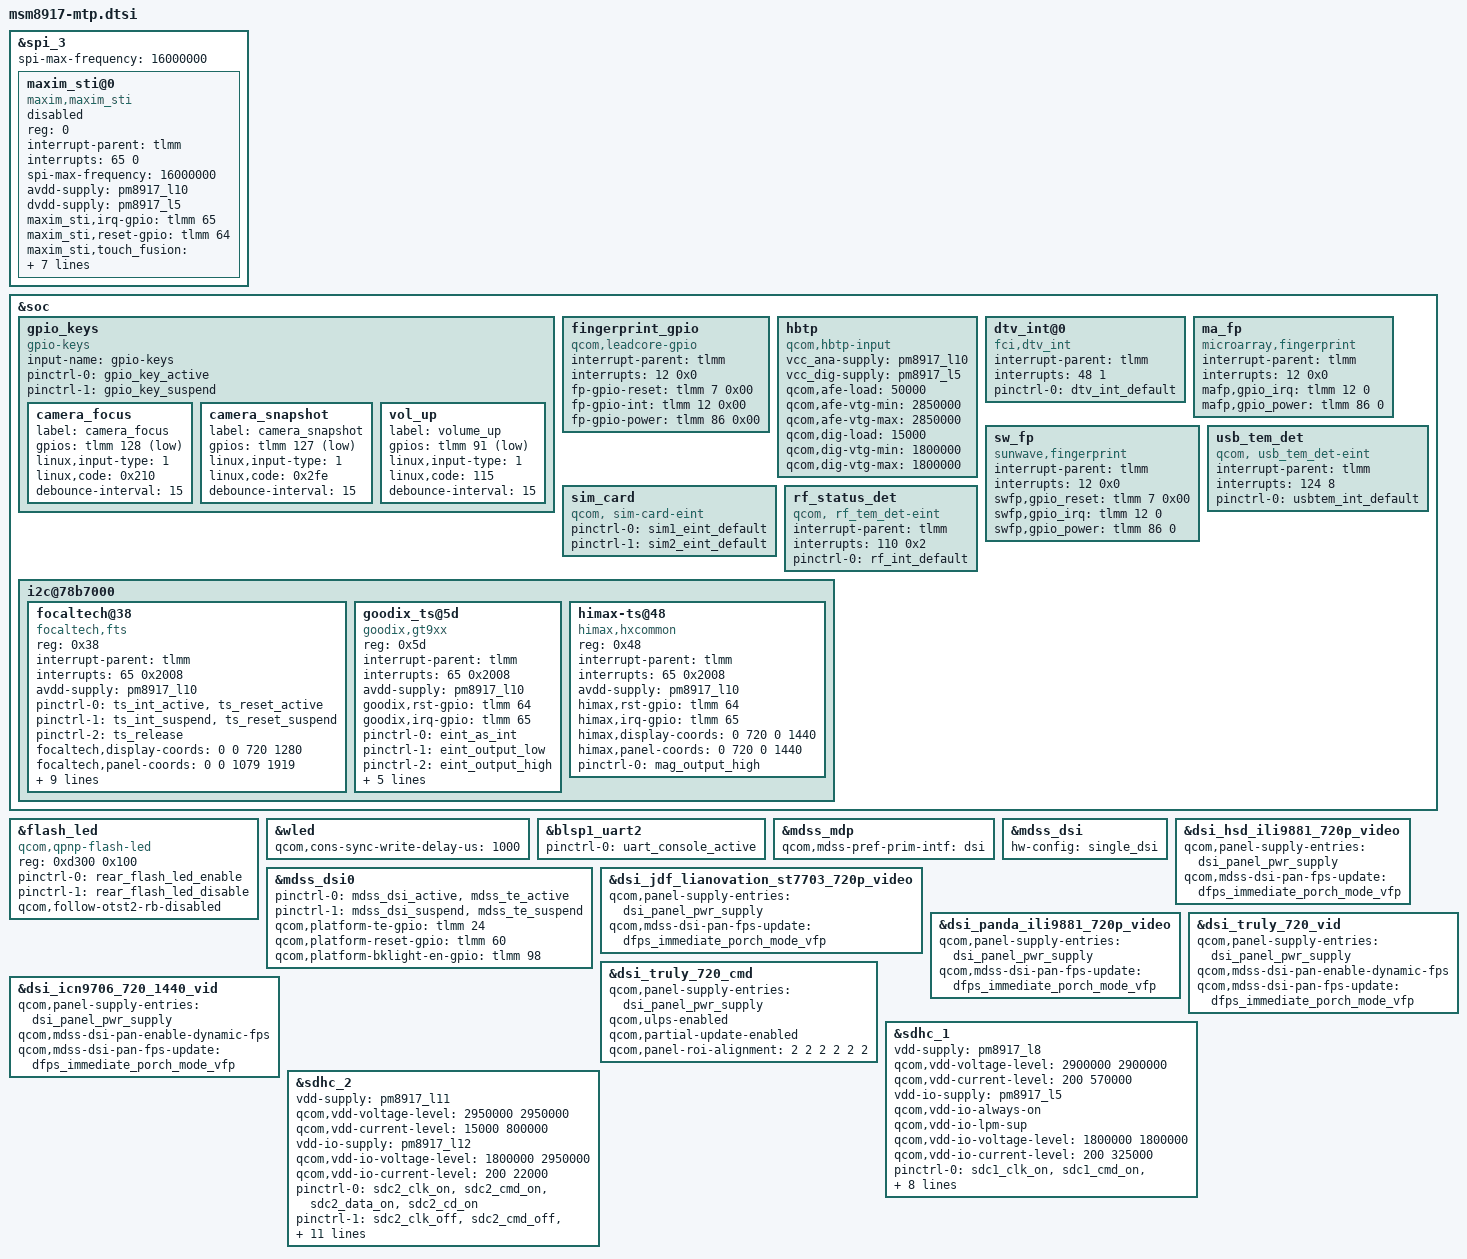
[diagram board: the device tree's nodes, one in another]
/*
 * Copyright (c) 2015-2017, The Linux Foundation. All rights reserved.
 *
 * This program is free software; you can redistribute it and/or modify
 * it under the terms of the GNU General Public License version 2 and
 * only version 2 as published by the Free Software Foundation.
 *
 * This program is distributed in the hope that it will be useful,
 * but WITHOUT ANY WARRANTY; without even the implied warranty of
 * MERCHANTABILITY or FITNESS FOR A PARTICULAR PURPOSE.  See the
 * GNU General Public License for more details.
 */

#include "msm8917-pinctrl.dtsi"
#include "msm8917-camera-sensor-mtp.dtsi"

&spi_3 { /* BLSP1 QUP3 */
	spi-max-frequency = <16000000>;
	maxim_sti@0 {
		status = "disabled";
		compatible = "maxim,maxim_sti";
		reg = <0>;
		interrupt-parent = <&tlmm>;
		interrupts = <65 0>;
		spi-max-frequency = <16000000>;
		avdd-supply = <&pm8917_l10>;
		dvdd-supply = <&pm8917_l5>;
		maxim_sti,irq-gpio = <&tlmm 65 0x00>;
		maxim_sti,reset-gpio = <&tlmm 64 0x00>;
		maxim_sti,touch_fusion = "/vendor/bin/touch_fusion";
		maxim_sti,config_file = "/etc/firmware/qtc800s.cfg";
		maxim_sti,fw_name = "qtc800s.bin";
		pinctrl-names = "pmx_ts_active","pmx_ts_suspend",
			"pmx_ts_release";
		pinctrl-0 = <&ts_int_active &ts_reset_active>;
		pinctrl-1 = <&ts_int_suspend &ts_reset_suspend>;
		pinctrl-2 = <&ts_release>;
	};
};

&soc {
	gpio_keys {
		compatible = "gpio-keys";
		input-name = "gpio-keys";
		pinctrl-names = "tlmm_gpio_key_active","tlmm_gpio_key_suspend";
		pinctrl-0 = <&gpio_key_active>;
		pinctrl-1 = <&gpio_key_suspend>;

		camera_focus {
			label = "camera_focus";
			gpios = <&tlmm 128 0x1>;
			linux,input-type = <1>;
			linux,code = <0x210>;
			debounce-interval = <15>;
		};

		camera_snapshot {
			label = "camera_snapshot";
			gpios = <&tlmm 127 0x1>;
			linux,input-type = <1>;
			linux,code = <0x2fe>;
			debounce-interval = <15>;
		};

		vol_up {
			label = "volume_up";
			gpios = <&tlmm 91 0x1>;
			linux,input-type = <1>;
			linux,code = <115>;
			debounce-interval = <15>;
		};
	};
       // add for E300 by leadcore fingerprint
	   fingerprint_gpio {
		compatible = "qcom,leadcore-gpio";
		interrupt-parent = <&tlmm>;
		interrupts = <12 0x0>;
		
		fp-gpio-reset = <&tlmm 7 0x00>;
		fp-gpio-int = <&tlmm  12 0x00>;
		fp-gpio-power = <&tlmm  86 0x00>;
		status = "okay";
	    };
	hbtp {
		compatible = "qcom,hbtp-input";
		vcc_ana-supply = <&pm8917_l10>;
		vcc_dig-supply = <&pm8917_l5>;
		qcom,afe-load = <50000>;
		qcom,afe-vtg-min = <2850000>;
		qcom,afe-vtg-max = <2850000>;
		qcom,dig-load = <15000>;
		qcom,dig-vtg-min = <1800000>;
		qcom,dig-vtg-max = <1800000>;
	};
	/* lihaiyan@wind-mobi.com 20171030 +++ */
	dtv_int@0 {
			compatible = "fci,dtv_int";
			interrupt-parent = <&tlmm>;
            interrupts = <48 1>;
			pinctrl-names = "default";
			pinctrl-0 = <&dtv_int_default>;
		};
	/* lihaiyan@wind-mobi.com 20171030 --- */
	
	/* add by microarray start */	
	ma_fp {
        	compatible = "microarray,fingerprint";
        	interrupt-parent = <&tlmm>;
        	interrupts = <12 0x0>;
       	 	mafp,gpio_irq = <&tlmm 12 0>;
       	 	mafp,gpio_power = <&tlmm 86 0>;
    	};
	/* add by microarray end */	
	
	/* add by sunwave start */	
	sw_fp {
        	compatible = "sunwave,fingerprint";
        	interrupt-parent = <&tlmm>;
        	interrupts = <12 0x0>;
		swfp,gpio_reset = <&tlmm 7 0x00>;
       	 	swfp,gpio_irq = <&tlmm 12 0>;
       	 	swfp,gpio_power = <&tlmm 86 0>;
	status = "okay";
    	};
    	/* add by sunwave end */	


	//liulinsheng@wind-mobi.com 20170824 begin
	usb_tem_det: usb_tem_det{
		compatible = "qcom, usb_tem_det-eint";
    		interrupt-parent = <&tlmm>;
		interrupts = <124 8>;       //2 falling  8 low
		pinctrl-names = "default";
		pinctrl-0 = <&usbtem_int_default>;
		status = "okay";
	};	
	//liulinsheng@wind-mobi.com 20170824 end
	
	//add by zhaozhensen@wind-mobi.com 20180110 begin
	sim_card: sim_card{
		compatible = "qcom, sim-card-eint";
		pinctrl-names = "sim1_default","sim2_default";
		pinctrl-0 = <&sim1_eint_default>;
		pinctrl-1 = <&sim2_eint_default>;
		status = "ok";
	};
	//add by zhaozhensen@wind-mobi.com 20180110 end
    //yutao@wind-mobi.com 20170824 begin

	rf_status_det: rf_status_det{
	compatible = "qcom, rf_tem_det-eint";
    interrupt-parent = <&tlmm>;
	interrupts = <110 0x2>;
	pinctrl-names = "rfstatus";
	pinctrl-0 = <&rf_int_default>;
	};
	
	//yutao@wind-mobi.com 20170824 end
	
	
	
	
	//hebiao@wind-mobi.com 20170824 begin	
	i2c@78b7000 {
         status = "ok";
         focaltech@38 {
             compatible = "focaltech,fts"; /* do not modify */
             reg = <0x38>;
             interrupt-parent = <&tlmm>;
             interrupts = <65 0x2008>;
             //vdd-supply = <&pm8937_l5>;
             avdd-supply = <&pm8917_l10>;
             pinctrl-names = "pmx_ts_active","pmx_ts_suspend",
                 "pmx_ts_release";
             pinctrl-0 = <&ts_int_active &ts_reset_active>;
             pinctrl-1 = <&ts_int_suspend &ts_reset_suspend>;
             pinctrl-2 = <&ts_release>;
             focaltech,display-coords = <0 0 720 1280>;
             focaltech,panel-coords = <0 0 1079 1919>;
             focaltech,reset-gpio = <&tlmm 64 0x00>;
             focaltech,mag-rst = <&tlmm 44 0x00>;
             focaltech,irq-gpio = <&tlmm 65 0x2008>;
	     focaltech,max-touch-number = <5>; /* 最大触点数 */
             focaltech,disable-gpios;
             focaltech,button-map = <158 139 172>;
             focaltech,resume-in-workqueue;
             /* Underlying clocks used by secure touch */
             clock-names = "iface_clk", "core_clk";
             clocks = <&clock_gcc clk_gcc_blsp1_ahb_clk>,
                 <&clock_gcc clk_gcc_blsp1_qup3_i2c_apps_clk>;
         };
     };
     
     i2c@78b7000 { 
  				status = "ok";
					goodix_ts@5d {
						compatible = "goodix,gt9xx";
						reg = <0x5d>;
						interrupt-parent = <&tlmm>;
						interrupts = <65 0x2008>;
						//vdd_ana-supply = <&pm8226_l19>;
						//vcc_i2c-supply = <&pm8226_lvs1>;
						avdd-supply = <&pm8917_l10>;
						goodix,rst-gpio = <&tlmm 64 0x00>;
						goodix,irq-gpio = <&tlmm 65 0x2008>;
//hebiao@wind-mobi.com 20171119 begin						
						pinctrl-names = "eint_as_int","eint_output_low", "eint_output_high", "mag_output_high";
						pinctrl-0 = <&eint_as_int>;
						pinctrl-1 = <&eint_output_low>;
						pinctrl-2 = <&eint_output_high>;
						pinctrl-3 = <&mag_output_high>;
						
						goodix,cfg-group0 = [
							45 D0 02 A0 05 0A 3C 10 21 CF 2D
							0F 3C 32 05 F3 00 00 60 62 00 11
							06 15 16 1A 14 87 27 DD 4C 4E D3
							07 7C 06 00 A2 34 11 00 0A 03 02
							19 00 40 0A 0C 62 2A 32 82 88 80
							A5 0A 1E 1E 04 A9 37 00 91 42 00
							7C 50 00 6A 62 00 5D 76 00 5D 00
							00 00 00 F0 50 40 FF F0 17 00 20
							00 03 00 00 00 00 53 64 04 04 0F
							28 00 00 00 00 00 0A 50 19 1E 00
							1E 28 19 18 17 16 15 14 13 12 11
							10 0F 0E 0B 04 05 0C 0D 08 09 0A
							03 02 01 00 07 06 FF FF FF FF 00
							02 04 05 06 08 0A 1E 1F 20 22 24
							29 2A FF FF FF 78 31 00 00 00 87
							70 12 00 00 00 00 14 00 7D 0F 66
							00 44 44 14 88 15 0F 00 00 00 00
							00 00 00 28 5A 00 00 00 00 32 00
							06 00 02 05 78 1C 14 14 28 00 00
							00 00 00 00 00 00 00 00 00 00 00
							00 00 00 00 00 00 20 01];
						goodix,cfg-group2 = [
							45 D0 02 A0 05 0A 3C 10 21 CF 2D
							0F 55 46 05 F3 00 00 60 62 00 11
							06 15 16 1A 14 87 27 DD 4C 4E D3
							07 7C 06 00 C2 33 11 00 00 00 00
							00 C0 40 0A 0C 64 2A 32 82 88 E0
							A5 0A 1E 1E 04 8B 37 00 78 42 00
							67 50 00 5A 62 00 50 76 00 50 00
							00 00 00 F0 50 40 FF F0 17 00 20
							00 00 00 00 00 00 53 64 04 04 0F
							28 00 00 00 00 00 0A 50 00 00 00
							00 28 19 18 17 16 15 14 13 12 11
							10 0F 0E 0B 04 05 0C 0D 08 09 0A
							03 02 01 00 07 06 FF FF FF FF 00
							02 04 05 06 08 0A 1E 1F 20 22 24
							29 2A FF FF FF 78 31 00 00 00 87
							70 12 00 1E 32 32 14 00 7D 0F 66
							00 44 44 14 88 15 0F 00 00 00 00
							00 00 00 28 5A 00 00 00 00 32 00
							06 00 02 05 78 1C 14 14 28 00 00
							00 7E 02 04 00 00 00 00 00 00 00
							00 00 00 00 00 00 A2 01];
			};
};   

	i2c@78b7000 { 
  				status = "ok";
					himax-ts@48 {
						compatible = "himax,hxcommon";
						reg = <0x48>;
						interrupt-parent = <&tlmm>;
						interrupts = <65 0x2008>;
						//vdd_ana-supply = <&pm8226_l19>;
						//vcc_i2c-supply = <&pm8226_lvs1>;
						avdd-supply = <&pm8917_l10>;
						himax,rst-gpio = <&tlmm 64 0x00>;
						himax,irq-gpio = <&tlmm 65 0x2008>;
						himax,display-coords = <0 720 0 1440 >;
						himax,panel-coords = <0 720 0 1440>;
						pinctrl-names = "mag_output_high";
						pinctrl-0 = <&mag_output_high>;
			};
	};   

//hebiao@wind-mobi.com 20170824 end		
};

&flash_led {
	compatible = "qcom,qpnp-flash-led";
	reg = <0xd300 0x100>;
	pinctrl-names = "flash_led_enable","flash_led_disable";
	pinctrl-0 = <&rear_flash_led_enable>;
	pinctrl-1 = <&rear_flash_led_disable>;
	qcom,follow-otst2-rb-disabled;
};

&wled {
	qcom,cons-sync-write-delay-us = <1000>;
};

/* lihaiyan@wind-mobi.com 20171024 +++
&pmi_haptic{
	qcom,actuator-type = "lra";
	qcom,wave-play-rate-us = <4165>;
	qcom,lra-auto-res-mode="qwd";
	qcom,lra-high-z="opt1";
	qcom,lra-res-cal-period = <0>;
};
*/

&blsp1_uart2 {
	status = "ok";
	pinctrl-names = "default";
	pinctrl-0 = <&uart_console_active>;
};

#include "msm8937-mdss-panels.dtsi"

&mdss_mdp {
	qcom,mdss-pref-prim-intf = "dsi";
};

&mdss_dsi {
	hw-config = "single_dsi";
};

&mdss_dsi0 {
//modified by hebiao at 20170831 begin
	//qcom,dsi-pref-prim-pan = <&dsi_hsd_ili9881_720p_video>;
	//qcom,dsi-pref-prim-pan = <&dsi_jdf_lianovation_st7703_720p_video>;
//modified by hebiao at 20170831 end
	pinctrl-names = "mdss_default", "mdss_sleep";
	pinctrl-0 = <&mdss_dsi_active &mdss_te_active>;
	pinctrl-1 = <&mdss_dsi_suspend &mdss_te_suspend>;

	qcom,platform-te-gpio = <&tlmm 24 0>;
	qcom,platform-reset-gpio = <&tlmm 60 0>;
	qcom,platform-bklight-en-gpio = <&tlmm 98 0>;
};

//hebiao@wind-mobi.com 20170831 begin
&dsi_hsd_ili9881_720p_video {
	qcom,panel-supply-entries = <&dsi_panel_pwr_supply>;
	//qcom,mdss-dsi-pan-enable-dynamic-fps;
	qcom,mdss-dsi-pan-fps-update = "dfps_immediate_porch_mode_vfp";
};
//hebiao@wind-mobi.com 20170831 end

//hebiao@wind-mobi.com 20170831 begin
&dsi_jdf_lianovation_st7703_720p_video {
	qcom,panel-supply-entries = <&dsi_panel_pwr_supply>;
	//qcom,mdss-dsi-pan-enable-dynamic-fps;
	qcom,mdss-dsi-pan-fps-update = "dfps_immediate_porch_mode_vfp";
};
//hebiao@wind-mobi.com 20170831 end

//hebiao@wind-mobi.com 20170831 begin
&dsi_panda_ili9881_720p_video {
	qcom,panel-supply-entries = <&dsi_panel_pwr_supply>;
	//qcom,mdss-dsi-pan-enable-dynamic-fps;
	qcom,mdss-dsi-pan-fps-update = "dfps_immediate_porch_mode_vfp";
};
//hebiao@wind-mobi.com 20170831 end



&dsi_truly_720_vid {
	qcom,panel-supply-entries = <&dsi_panel_pwr_supply>;
	qcom,mdss-dsi-pan-enable-dynamic-fps;
	qcom,mdss-dsi-pan-fps-update = "dfps_immediate_porch_mode_vfp";
};

&dsi_truly_720_cmd {
	qcom,panel-supply-entries = <&dsi_panel_pwr_supply>;
	qcom,ulps-enabled;
	qcom,partial-update-enabled;
	qcom,panel-roi-alignment = <2 2 2 2 2 2>;
};

&dsi_icn9706_720_1440_vid {
	qcom,panel-supply-entries = <&dsi_panel_pwr_supply>;
	qcom,mdss-dsi-pan-enable-dynamic-fps;
	qcom,mdss-dsi-pan-fps-update = "dfps_immediate_porch_mode_vfp";
};

&sdhc_1 {
	/* device core power supply */
	vdd-supply = <&pm8917_l8>;
	qcom,vdd-voltage-level = <2900000 2900000>;
	qcom,vdd-current-level = <200 570000>;

	/* device communication power supply */
	vdd-io-supply = <&pm8917_l5>;
	qcom,vdd-io-always-on;
	qcom,vdd-io-lpm-sup;
	qcom,vdd-io-voltage-level = <1800000 1800000>;
	qcom,vdd-io-current-level = <200 325000>;

	pinctrl-names = "active", "sleep";
	pinctrl-0 = <&sdc1_clk_on &sdc1_cmd_on &sdc1_data_on &sdc1_rclk_on>;
	pinctrl-1 = <&sdc1_clk_off &sdc1_cmd_off &sdc1_data_off &sdc1_rclk_off>;

	qcom,clk-rates = <400000 20000000 25000000 50000000 100000000 192000000
								384000000>;
	qcom,nonremovable;
	qcom,bus-speed-mode = "HS400_1p8v", "HS200_1p8v", "DDR_1p8v";

	status = "ok";
};

&sdhc_2 {
	/* device core power supply */
	vdd-supply = <&pm8917_l11>;
	qcom,vdd-voltage-level = <2950000 2950000>;
	qcom,vdd-current-level = <15000 800000>;

	/* device communication power supply */
	vdd-io-supply = <&pm8917_l12>;
	qcom,vdd-io-voltage-level = <1800000 2950000>;
	qcom,vdd-io-current-level = <200 22000>;

	pinctrl-names = "active", "sleep";
	pinctrl-0 = <&sdc2_clk_on &sdc2_cmd_on &sdc2_data_on &sdc2_cd_on>;
	pinctrl-1 = <&sdc2_clk_off &sdc2_cmd_off &sdc2_data_off>;

	#address-cells = <0>;
	interrupt-parent = <&sdhc_2>;
	interrupts = <0 1 2>;
	#interrupt-cells = <1>;
	interrupt-map-mask = <0xffffffff>;
	interrupt-map = <0 &intc 0 125 0
		1 &intc 0 221 0
		2 &tlmm 67 0>;
	interrupt-names = "hc_irq", "pwr_irq", "status_irq";
	cd-gpios = <&tlmm 67 0x0>; /* lihaiyan@wind-mobi.com out:low in:high  qcom config out level*/

	qcom,clk-rates = <400000 20000000 25000000 50000000 100000000
								200000000>;
	qcom,bus-speed-mode = "SDR12", "SDR25", "SDR50", "DDR50", "SDR104";

	status = "ok";
};
